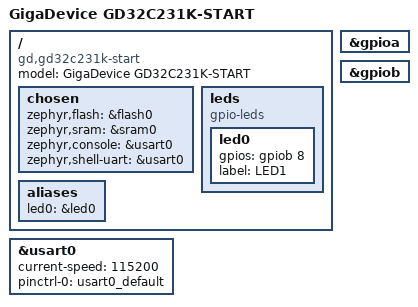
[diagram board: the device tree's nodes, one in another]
/*
 * Copyright (c) 2026 GigaDevice Semiconductor Inc.
 * SPDX-License-Identifier: Apache-2.0
 */

/dts-v1/;

#include <gd/gd32c2x1/gd32c231k8.dtsi>
#include "gd32c231k_start-pinctrl.dtsi"

/ {
	model = "GigaDevice GD32C231K-START";
	compatible = "gd,gd32c231k-start";

	chosen {
		zephyr,flash = &flash0;
		zephyr,sram = &sram0;
		zephyr,console = &usart0;
		zephyr,shell-uart = &usart0;
	};

	leds {
		compatible = "gpio-leds";
		led0: led0 {
			gpios = <&gpiob 8 GPIO_ACTIVE_HIGH>;
			label = "LED1";
		};
	};

	aliases {
		led0 = &led0;
	};
};

&gpioa {
	status = "okay";
};

&gpiob {
	status = "okay";
};

&usart0 {
	status = "okay";
	current-speed = <115200>;
	pinctrl-0 = <&usart0_default>;
	pinctrl-names = "default";
};
